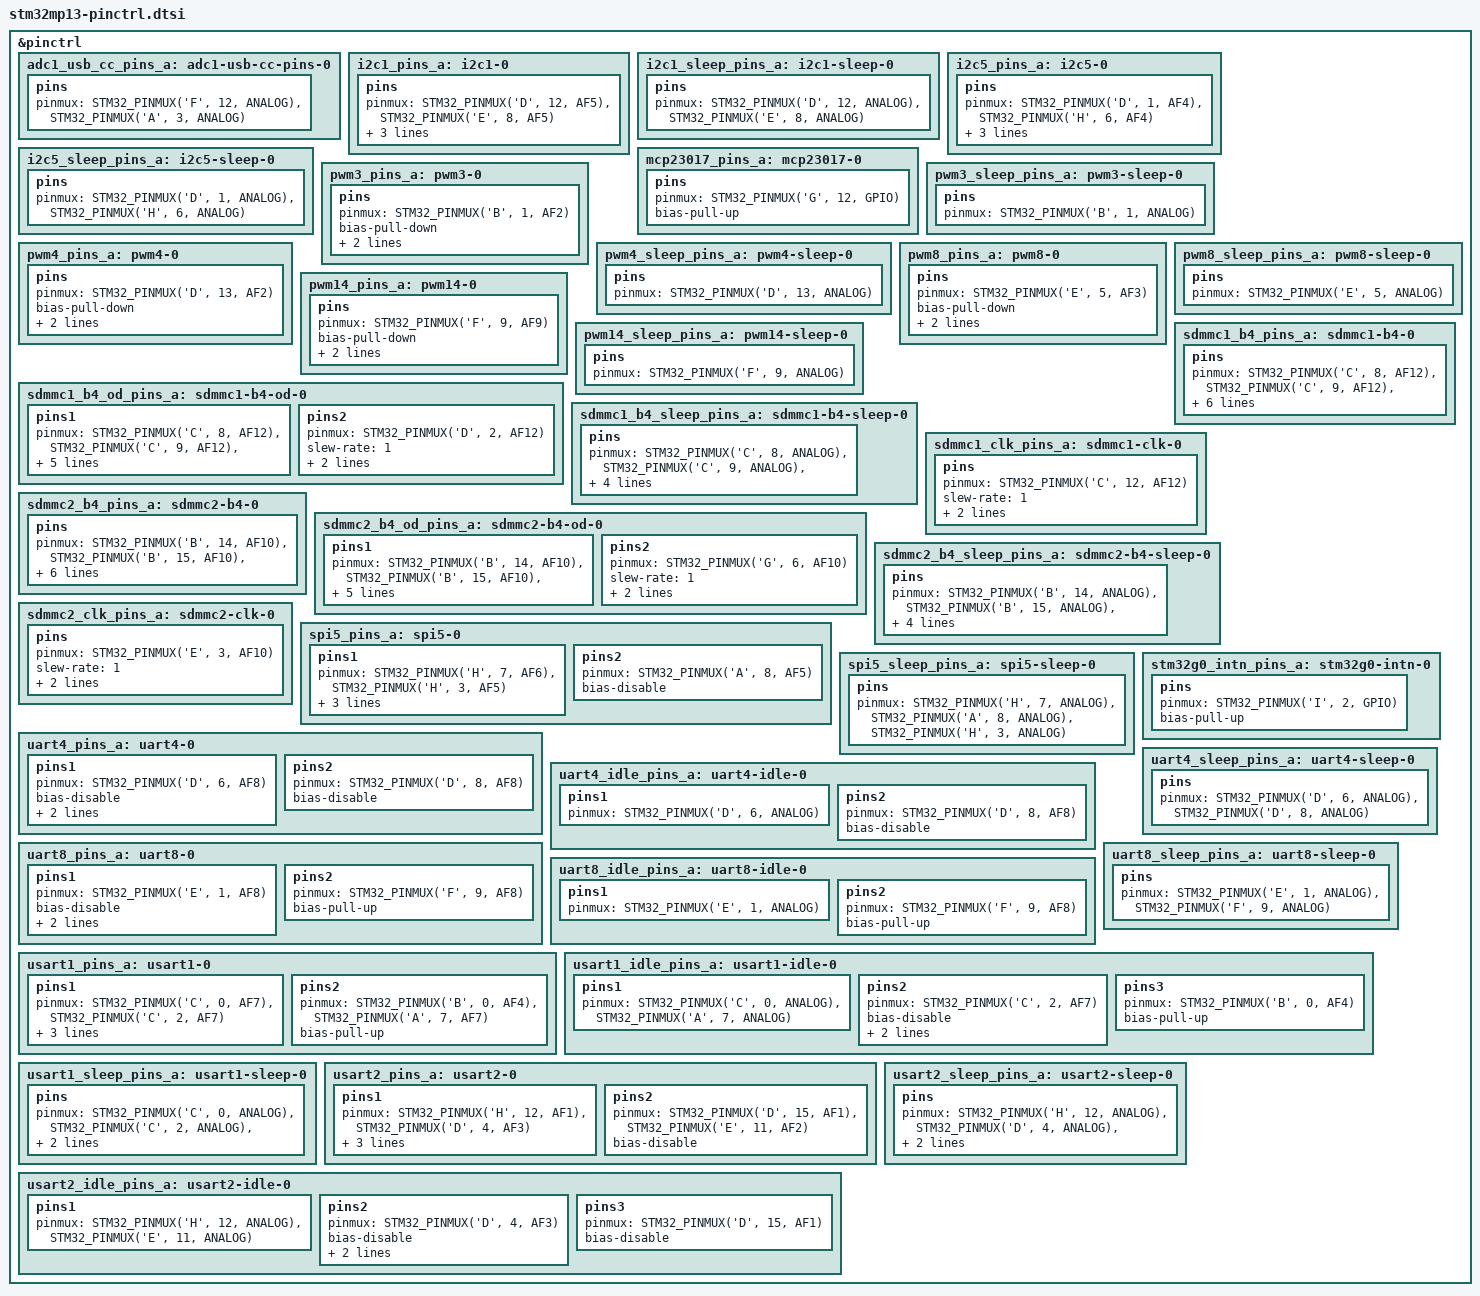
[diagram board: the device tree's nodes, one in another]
#include <dt-bindings/pinctrl/stm32-pinfunc.h>
&pinctrl {
	adc1_usb_cc_pins_a: adc1-usb-cc-pins-0 {
		pins {
			pinmux = <STM32_PINMUX('F', 12, ANALOG)>,  
				 <STM32_PINMUX('A', 3, ANALOG)>;  
		};
	};
	i2c1_pins_a: i2c1-0 {
		pins {
			pinmux = <STM32_PINMUX('D', 12, AF5)>,  
				 <STM32_PINMUX('E', 8, AF5)>;  
			bias-disable;
			drive-open-drain;
			slew-rate = <0>;
		};
	};
	i2c1_sleep_pins_a: i2c1-sleep-0 {
		pins {
			pinmux = <STM32_PINMUX('D', 12, ANALOG)>,  
				 <STM32_PINMUX('E', 8, ANALOG)>;  
		};
	};
	i2c5_pins_a: i2c5-0 {
		pins {
			pinmux = <STM32_PINMUX('D', 1, AF4)>,  
				 <STM32_PINMUX('H', 6, AF4)>;  
			bias-disable;
			drive-open-drain;
			slew-rate = <0>;
		};
	};
	i2c5_sleep_pins_a: i2c5-sleep-0 {
		pins {
			pinmux = <STM32_PINMUX('D', 1, ANALOG)>,  
				 <STM32_PINMUX('H', 6, ANALOG)>;  
		};
	};
	mcp23017_pins_a: mcp23017-0 {
		pins {
			pinmux = <STM32_PINMUX('G', 12, GPIO)>;
			bias-pull-up;
		};
	};
	pwm3_pins_a: pwm3-0 {
		pins {
			pinmux = <STM32_PINMUX('B', 1, AF2)>;  
			bias-pull-down;
			drive-push-pull;
			slew-rate = <0>;
		};
	};
	pwm3_sleep_pins_a: pwm3-sleep-0 {
		pins {
			pinmux = <STM32_PINMUX('B', 1, ANALOG)>;  
		};
	};
	pwm4_pins_a: pwm4-0 {
		pins {
			pinmux = <STM32_PINMUX('D', 13, AF2)>;  
			bias-pull-down;
			drive-push-pull;
			slew-rate = <0>;
		};
	};
	pwm4_sleep_pins_a: pwm4-sleep-0 {
		pins {
			pinmux = <STM32_PINMUX('D', 13, ANALOG)>;  
		};
	};
	pwm8_pins_a: pwm8-0 {
		pins {
			pinmux = <STM32_PINMUX('E', 5, AF3)>;  
			bias-pull-down;
			drive-push-pull;
			slew-rate = <0>;
		};
	};
	pwm8_sleep_pins_a: pwm8-sleep-0 {
		pins {
			pinmux = <STM32_PINMUX('E', 5, ANALOG)>;  
		};
	};
	pwm14_pins_a: pwm14-0 {
		pins {
			pinmux = <STM32_PINMUX('F', 9, AF9)>;  
			bias-pull-down;
			drive-push-pull;
			slew-rate = <0>;
		};
	};
	pwm14_sleep_pins_a: pwm14-sleep-0 {
		pins {
			pinmux = <STM32_PINMUX('F', 9, ANALOG)>;  
		};
	};
	sdmmc1_b4_pins_a: sdmmc1-b4-0 {
		pins {
			pinmux = <STM32_PINMUX('C', 8, AF12)>,  
				 <STM32_PINMUX('C', 9, AF12)>,  
				 <STM32_PINMUX('C', 10, AF12)>,  
				 <STM32_PINMUX('C', 11, AF12)>,  
				 <STM32_PINMUX('D', 2, AF12)>;  
			slew-rate = <1>;
			drive-push-pull;
			bias-disable;
		};
	};
	sdmmc1_b4_od_pins_a: sdmmc1-b4-od-0 {
		pins1 {
			pinmux = <STM32_PINMUX('C', 8, AF12)>,  
				 <STM32_PINMUX('C', 9, AF12)>,  
				 <STM32_PINMUX('C', 10, AF12)>,  
				 <STM32_PINMUX('C', 11, AF12)>;  
			slew-rate = <1>;
			drive-push-pull;
			bias-disable;
		};
		pins2 {
			pinmux = <STM32_PINMUX('D', 2, AF12)>;  
			slew-rate = <1>;
			drive-open-drain;
			bias-disable;
		};
	};
	sdmmc1_b4_sleep_pins_a: sdmmc1-b4-sleep-0 {
		pins {
			pinmux = <STM32_PINMUX('C', 8, ANALOG)>,  
				 <STM32_PINMUX('C', 9, ANALOG)>,  
				 <STM32_PINMUX('C', 10, ANALOG)>,  
				 <STM32_PINMUX('C', 11, ANALOG)>,  
				 <STM32_PINMUX('C', 12, ANALOG)>,  
				 <STM32_PINMUX('D', 2, ANALOG)>;  
		};
	};
	sdmmc1_clk_pins_a: sdmmc1-clk-0 {
		pins {
			pinmux = <STM32_PINMUX('C', 12, AF12)>;  
			slew-rate = <1>;
			drive-push-pull;
			bias-disable;
		};
	};
	sdmmc2_b4_pins_a: sdmmc2-b4-0 {
		pins {
			pinmux = <STM32_PINMUX('B', 14, AF10)>,  
				 <STM32_PINMUX('B', 15, AF10)>,  
				 <STM32_PINMUX('B', 3, AF10)>,  
				 <STM32_PINMUX('B', 4, AF10)>,  
				 <STM32_PINMUX('G', 6, AF10)>;  
			slew-rate = <1>;
			drive-push-pull;
			bias-pull-up;
		};
	};
	sdmmc2_b4_od_pins_a: sdmmc2-b4-od-0 {
		pins1 {
			pinmux = <STM32_PINMUX('B', 14, AF10)>,  
				 <STM32_PINMUX('B', 15, AF10)>,  
				 <STM32_PINMUX('B', 3, AF10)>,  
				 <STM32_PINMUX('B', 4, AF10)>;  
			slew-rate = <1>;
			drive-push-pull;
			bias-pull-up;
		};
		pins2 {
			pinmux = <STM32_PINMUX('G', 6, AF10)>;  
			slew-rate = <1>;
			drive-open-drain;
			bias-pull-up;
		};
	};
	sdmmc2_b4_sleep_pins_a: sdmmc2-b4-sleep-0 {
		pins {
			pinmux = <STM32_PINMUX('B', 14, ANALOG)>,  
				 <STM32_PINMUX('B', 15, ANALOG)>,  
				 <STM32_PINMUX('B', 3, ANALOG)>,  
				 <STM32_PINMUX('B', 4, ANALOG)>,  
				 <STM32_PINMUX('E', 3, ANALOG)>,  
				 <STM32_PINMUX('G', 6, ANALOG)>;  
		};
	};
	sdmmc2_clk_pins_a: sdmmc2-clk-0 {
		pins {
			pinmux = <STM32_PINMUX('E', 3, AF10)>;  
			slew-rate = <1>;
			drive-push-pull;
			bias-pull-up;
		};
	};
	spi5_pins_a: spi5-0 {
		pins1 {
			pinmux = <STM32_PINMUX('H', 7, AF6)>,  
				 <STM32_PINMUX('H', 3, AF5)>;  
			bias-disable;
			drive-push-pull;
			slew-rate = <1>;
		};
		pins2 {
			pinmux = <STM32_PINMUX('A', 8, AF5)>;  
			bias-disable;
		};
	};
	spi5_sleep_pins_a: spi5-sleep-0 {
		pins {
			pinmux = <STM32_PINMUX('H', 7, ANALOG)>,  
				 <STM32_PINMUX('A', 8, ANALOG)>,  
				 <STM32_PINMUX('H', 3, ANALOG)>;  
		};
	};
	stm32g0_intn_pins_a: stm32g0-intn-0 {
		pins {
			pinmux = <STM32_PINMUX('I', 2, GPIO)>;
			bias-pull-up;
		};
	};
	uart4_pins_a: uart4-0 {
		pins1 {
			pinmux = <STM32_PINMUX('D', 6, AF8)>;  
			bias-disable;
			drive-push-pull;
			slew-rate = <0>;
		};
		pins2 {
			pinmux = <STM32_PINMUX('D', 8, AF8)>;  
			bias-disable;
		};
	};
	uart4_idle_pins_a: uart4-idle-0 {
		pins1 {
			pinmux = <STM32_PINMUX('D', 6, ANALOG)>;  
		};
		pins2 {
			pinmux = <STM32_PINMUX('D', 8, AF8)>;  
			bias-disable;
		};
	};
	uart4_sleep_pins_a: uart4-sleep-0 {
		pins {
			pinmux = <STM32_PINMUX('D', 6, ANALOG)>,  
				 <STM32_PINMUX('D', 8, ANALOG)>;  
		};
	};
	uart8_pins_a: uart8-0 {
		pins1 {
			pinmux = <STM32_PINMUX('E', 1, AF8)>;  
			bias-disable;
			drive-push-pull;
			slew-rate = <0>;
		};
		pins2 {
			pinmux = <STM32_PINMUX('F', 9, AF8)>;  
			bias-pull-up;
		};
	};
	uart8_idle_pins_a: uart8-idle-0 {
		pins1 {
			pinmux = <STM32_PINMUX('E', 1, ANALOG)>;  
		};
		pins2 {
			pinmux = <STM32_PINMUX('F', 9, AF8)>;  
			bias-pull-up;
		};
	};
	uart8_sleep_pins_a: uart8-sleep-0 {
		pins {
			pinmux = <STM32_PINMUX('E', 1, ANALOG)>,  
				 <STM32_PINMUX('F', 9, ANALOG)>;  
		};
	};
	usart1_pins_a: usart1-0 {
		pins1 {
			pinmux = <STM32_PINMUX('C', 0, AF7)>,  
				 <STM32_PINMUX('C', 2, AF7)>;  
			bias-disable;
			drive-push-pull;
			slew-rate = <0>;
		};
		pins2 {
			pinmux = <STM32_PINMUX('B', 0, AF4)>,  
				 <STM32_PINMUX('A', 7, AF7)>;  
			bias-pull-up;
		};
	};
	usart1_idle_pins_a: usart1-idle-0 {
		pins1 {
			pinmux = <STM32_PINMUX('C', 0, ANALOG)>,  
				 <STM32_PINMUX('A', 7, ANALOG)>;  
		};
		pins2 {
			pinmux = <STM32_PINMUX('C', 2, AF7)>;  
			bias-disable;
			drive-push-pull;
			slew-rate = <0>;
		};
		pins3 {
			pinmux = <STM32_PINMUX('B', 0, AF4)>;  
			bias-pull-up;
		};
	};
	usart1_sleep_pins_a: usart1-sleep-0 {
		pins {
			pinmux = <STM32_PINMUX('C', 0, ANALOG)>,  
				 <STM32_PINMUX('C', 2, ANALOG)>,  
				 <STM32_PINMUX('A', 7, ANALOG)>,  
				 <STM32_PINMUX('B', 0, ANALOG)>;  
		};
	};
	usart2_pins_a: usart2-0 {
		pins1 {
			pinmux = <STM32_PINMUX('H', 12, AF1)>,  
				 <STM32_PINMUX('D', 4, AF3)>;  
			bias-disable;
			drive-push-pull;
			slew-rate = <0>;
		};
		pins2 {
			pinmux = <STM32_PINMUX('D', 15, AF1)>,  
				 <STM32_PINMUX('E', 11, AF2)>;  
			bias-disable;
		};
	};
	usart2_idle_pins_a: usart2-idle-0 {
		pins1 {
			pinmux = <STM32_PINMUX('H', 12, ANALOG)>,  
				 <STM32_PINMUX('E', 11, ANALOG)>;  
		};
		pins2 {
			pinmux = <STM32_PINMUX('D', 4, AF3)>;  
			bias-disable;
			drive-push-pull;
			slew-rate = <0>;
		};
		pins3 {
			pinmux = <STM32_PINMUX('D', 15, AF1)>;  
			bias-disable;
		};
	};
	usart2_sleep_pins_a: usart2-sleep-0 {
		pins {
			pinmux = <STM32_PINMUX('H', 12, ANALOG)>,  
				 <STM32_PINMUX('D', 4, ANALOG)>,  
				 <STM32_PINMUX('D', 15, ANALOG)>,  
				 <STM32_PINMUX('E', 11, ANALOG)>;  
		};
	};
};
